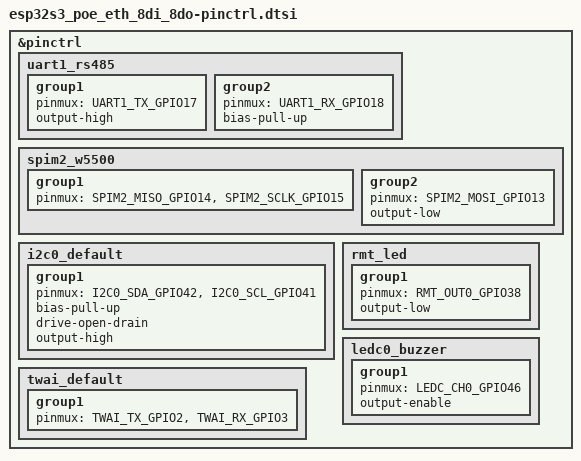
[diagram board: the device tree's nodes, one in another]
/*
 * Pin map of the Waveshare ESP32-S3-POE-ETH-8DI-8DO (from the Waveshare
 * wiki pin table and its Arduino demo, see zephyr/README.md).
 *
 * SPDX-License-Identifier: Apache-2.0
 */

#include <zephyr/dt-bindings/pinctrl/esp32s3-pinctrl.h>

&pinctrl {
	/* Isolated RS485: TX GPIO17, RX GPIO18; DE/RTS GPIO21 is driven as a
	 * GPIO by the Modbus subsystem (de-gpios), see the board DTS.
	 */
	uart1_rs485: uart1_rs485 {
		group1 {
			pinmux = <UART1_TX_GPIO17>;
			output-high;
		};

		group2 {
			pinmux = <UART1_RX_GPIO18>;
			bias-pull-up;
		};
	};

	/* W5500: MOSI 13, MISO 14, SCLK 15 (CS 16 is a GPIO chip select) */
	spim2_w5500: spim2_w5500 {
		group1 {
			pinmux = <SPIM2_MISO_GPIO14>,
				 <SPIM2_SCLK_GPIO15>;
		};

		group2 {
			pinmux = <SPIM2_MOSI_GPIO13>;
			output-low;
		};
	};

	/* Shared I2C bus: TCA9554 (0x20, outputs) and PCF85063 RTC (0x51) */
	i2c0_default: i2c0_default {
		group1 {
			pinmux = <I2C0_SDA_GPIO42>,
				 <I2C0_SCL_GPIO41>;
			bias-pull-up;
			drive-open-drain;
			output-high;
		};
	};

	/* WS2812-type RGB LED data line on GPIO38, driven by RMT channel 0 */
	rmt_led: rmt_led {
		group1 {
			pinmux = <RMT_OUT0_GPIO38>;
			output-low;
		};
	};

	/* Passive buzzer on GPIO46 (PWM driven in the Waveshare demo) */
	ledc0_buzzer: ledc0_buzzer {
		group1 {
			pinmux = <LEDC_CH0_GPIO46>;
			output-enable;
		};
	};

	/* Isolated CAN (TWAI): TX GPIO2, RX GPIO3 */
	twai_default: twai_default {
		group1 {
			pinmux = <TWAI_TX_GPIO2>,
				 <TWAI_RX_GPIO3>;
		};
	};
};
